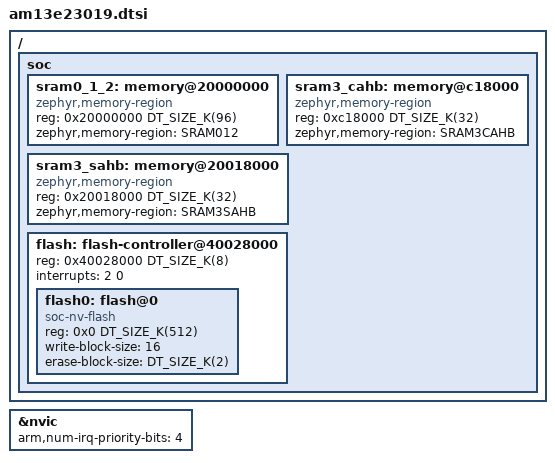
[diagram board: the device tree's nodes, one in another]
/*
 * Copyright (c) 2026 Texas Instruments Incorporated
 *
 * SPDX-License-Identifier: Apache-2.0
 */

#include "am13e.dtsi"

/ {
	#address-cells = <1>;
	#size-cells = <1>;

	soc {
		sram0_1_2: memory@20000000 {
			compatible = "zephyr,memory-region";
			reg = <0x20000000 DT_SIZE_K(96)>;
			zephyr,memory-region = "SRAM012";
		};

		sram3_cahb: memory@c18000 {
			compatible = "zephyr,memory-region";
			reg = <0xc18000 DT_SIZE_K(32)>;
			zephyr,memory-region = "SRAM3CAHB";
		};

		sram3_sahb: memory@20018000 {
			compatible = "zephyr,memory-region";
			reg = <0x20018000 DT_SIZE_K(32)>;
			zephyr,memory-region = "SRAM3SAHB";
		};

		flash: flash-controller@40028000 {
			reg = <0x40028000 DT_SIZE_K(8)>;
			ranges;
			interrupts = <2 0>;

			#address-cells = <1>;
			#size-cells = <1>;

			flash0: flash@0 {
				compatible = "soc-nv-flash";
				reg = <0x0 DT_SIZE_K(512)>;
				ranges = <0x0 0x0 DT_SIZE_K(512)>;

				write-block-size = <16>;
				erase-block-size = <DT_SIZE_K(2)>;

				#address-cells = <1>;
				#size-cells = <1>;
			};
		};
	};
};

&nvic {
	arm,num-irq-priority-bits = <4>;
};
